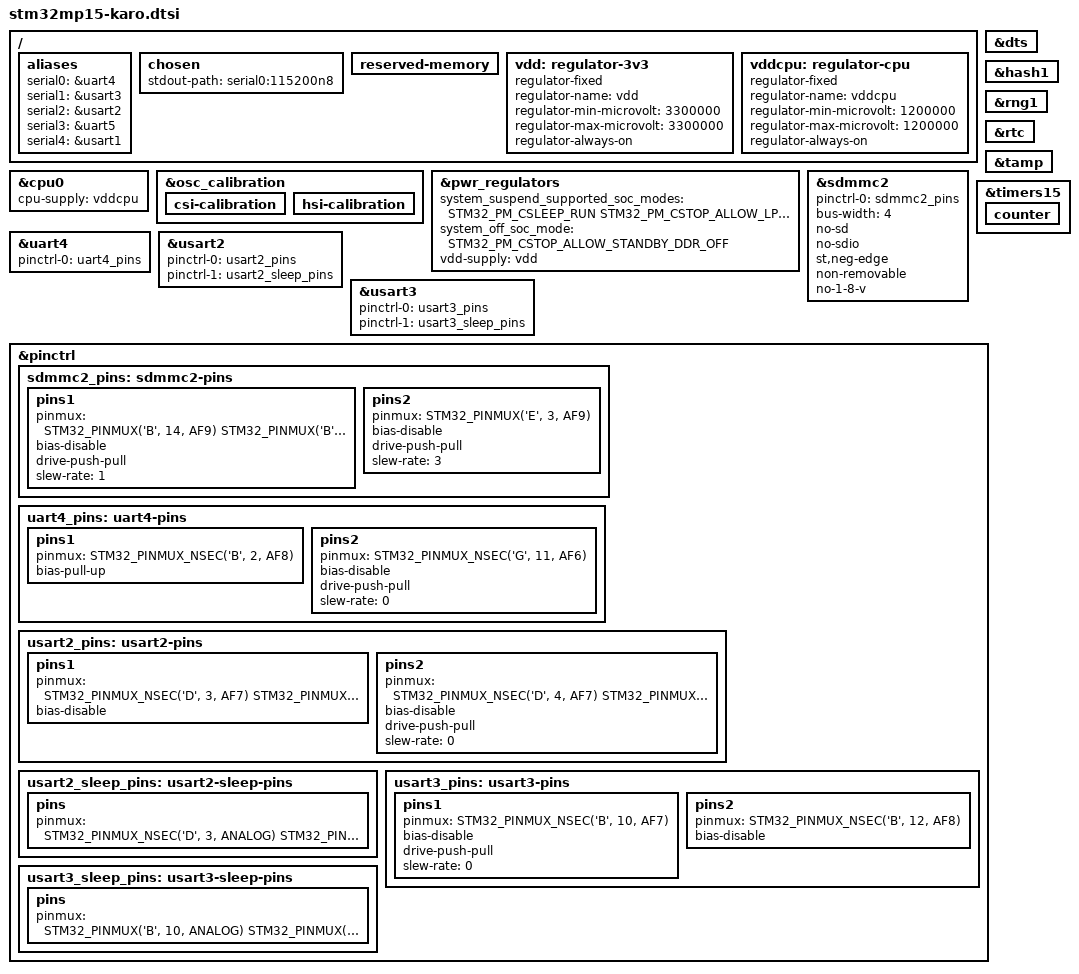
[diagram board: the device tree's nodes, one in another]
// SPDX-License-Identifier: (GPL-2.0-or-later OR BSD-3-Clause)
/*
 * Copyright (C) 2021 Lothar Waßmann <LW@KARO-electronics.de>
 * Copyright (C) 2024 Markus Bauer <MB@KARO-electronics.de>
 */

#include <dt-bindings/clock/stm32mp1-clksrc.h>
#include <dt-bindings/gpio/stm32mp_gpio.h>
#include <dt-bindings/pinctrl/stm32-pinfunc.h>
#include <dt-bindings/power/stm32mp1-power.h>
#include <dt-bindings/regulator/st,stm32mp15-regulator.h>
#include <dt-bindings/soc/stm32mp-tzc400-macro.h>
#include <dt-bindings/soc/stm32mp15-etzpc.h>
#include <dt-bindings/soc/stm32mp15-tzc400.h>

#include "stm32mp15xc.dtsi"

/ {
	aliases {
		serial0 = &uart4;
		serial1 = &usart3;
		serial2 = &usart2;
		serial3 = &uart5;
		serial4 = &usart1;
	};

	chosen {
		stdout-path = "serial0:115200n8";
	};

	reserved-memory {
		#address-cells = <1>;
		#size-cells = <1>;
		ranges;
	};

	vdd: regulator-3v3 {
		compatible = "regulator-fixed";
		regulator-name = "vdd";
		regulator-min-microvolt = <3300000>;
		regulator-max-microvolt = <3300000>;
		regulator-always-on;
	};

	vddcpu: regulator-cpu {
		compatible = "regulator-fixed";
		regulator-name = "vddcpu";
		regulator-min-microvolt = <1200000>;
		regulator-max-microvolt = <1200000>;
		regulator-always-on;
	};
};

&cpu0 {
	cpu-supply = <&vddcpu>;
};

&dts {
	status = "okay";
};

&hash1 {
	status = "okay";
};

&osc_calibration {
	csi-calibration {
		status = "okay";
	};

	hsi-calibration {
		status = "okay";
	};
};

&pwr_regulators {
	system_suspend_supported_soc_modes = <
		STM32_PM_CSLEEP_RUN
		STM32_PM_CSTOP_ALLOW_LP_STOP
		STM32_PM_CSTOP_ALLOW_STANDBY_DDR_SR
	>;
	system_off_soc_mode = <STM32_PM_CSTOP_ALLOW_STANDBY_DDR_OFF>;
 	vdd-supply = <&vdd>;
};

&rng1 {
	status = "okay";
};

&rtc {
	status = "okay";
};

&sdmmc2 {
	/* eMMC */
	pinctrl-names = "default";
	pinctrl-0 = <&sdmmc2_pins>;
	bus-width = <4>;
	no-sd;
	no-sdio;
	st,neg-edge;
	non-removable;
	no-1-8-v;
	status = "okay";
};

&tamp {
	status = "okay";
};

&timers15 {
	status = "okay";

	counter {
		status = "okay";
	};
};

&uart4 {
	pinctrl-names = "default";
	pinctrl-0 = <&uart4_pins>;
	status = "okay";
};

&usart2 {
	pinctrl-names = "default", "sleep";
	pinctrl-0 = <&usart2_pins>;
	pinctrl-1 = <&usart2_sleep_pins>;
};

&usart3 {
	pinctrl-names = "default", "sleep";
	pinctrl-0 = <&usart3_pins>;
	pinctrl-1 = <&usart3_sleep_pins>;
};

&pinctrl {
	sdmmc2_pins: sdmmc2-pins {
		pins1 {
			pinmux = <
				  STM32_PINMUX('B', 14, AF9)	/* SDMMC2_D0 */
				  STM32_PINMUX('B', 15, AF9)	/* SDMMC2_D1 */
				  STM32_PINMUX('B', 3, AF9)	/* SDMMC2_D2 */
				  STM32_PINMUX('B', 4, AF9)	/* SDMMC2_D3 */
				  STM32_PINMUX('A', 8, AF9)	/* SDMMC2_D4 */
				  STM32_PINMUX('B', 9, AF9)	/* SDMMC2_D5 */
				  STM32_PINMUX('C', 6, AF9)	/* SDMMC2_D6 */
				  STM32_PINMUX('C', 7, AF9)	/* SDMMC2_D7 */
				  STM32_PINMUX('G', 6, AF10)	/* SDMMC2_CMD */
			>;
			bias-disable;
			drive-push-pull;
			slew-rate = <1>;
		};

		pins2 {
			pinmux = <STM32_PINMUX('E', 3, AF9)>; /* SDMMC2_CK */
			bias-disable;
			drive-push-pull;
			slew-rate = <3>;
		};
	};

	uart4_pins: uart4-pins {
		pins1 {
			pinmux = <STM32_PINMUX_NSEC('B', 2, AF8)>; /* UART4_RX */
			bias-pull-up;
		};

		pins2 {
			pinmux = <STM32_PINMUX_NSEC('G', 11, AF6)>; /* UART4_TX */
			bias-disable;
			drive-push-pull;
			slew-rate = <0>;
		};
	};

	usart2_pins: usart2-pins {
		pins1 {
			pinmux = <
				  STM32_PINMUX_NSEC('D', 3, AF7) /* USART2_CTS */
				  STM32_PINMUX_NSEC('D', 6, AF7) /* USART2_RX */
			>;
			bias-disable;
		};

		pins2 {
			pinmux = <
				  STM32_PINMUX_NSEC('D', 4, AF7) /* USART2_RTS */
				  STM32_PINMUX_NSEC('D', 5, AF7) /* USART2_TX */
			>;
			bias-disable;
			drive-push-pull;
			slew-rate = <0>;
		};
	};

	usart2_sleep_pins: usart2-sleep-pins {
		pins {
			pinmux = <
				  STM32_PINMUX_NSEC('D', 3, ANALOG) /* USART2_CTS */
				  STM32_PINMUX_NSEC('D', 4, ANALOG) /* USART2_RTS */
				  STM32_PINMUX_NSEC('D', 5, ANALOG) /* USART2_TX */
				  STM32_PINMUX_NSEC('D', 6, ANALOG) /* USART2_RX */
			>;
		};
	};

	usart3_pins: usart3-pins {
		pins1 {
			pinmux = <STM32_PINMUX_NSEC('B', 10, AF7)>; /* USART3_TX */
			bias-disable;
			drive-push-pull;
			slew-rate = <0>;
		};

		pins2 {
			pinmux = <STM32_PINMUX_NSEC('B', 12, AF8)>; /* USART3_RX */
			bias-disable;
		};
	};

	usart3_sleep_pins: usart3-sleep-pins {
		pins {
			pinmux = <STM32_PINMUX('B', 10, ANALOG) /* USART3_TX */
				  STM32_PINMUX('B', 12, ANALOG) /* USART3_RX */
			>;
		};
	};
};
